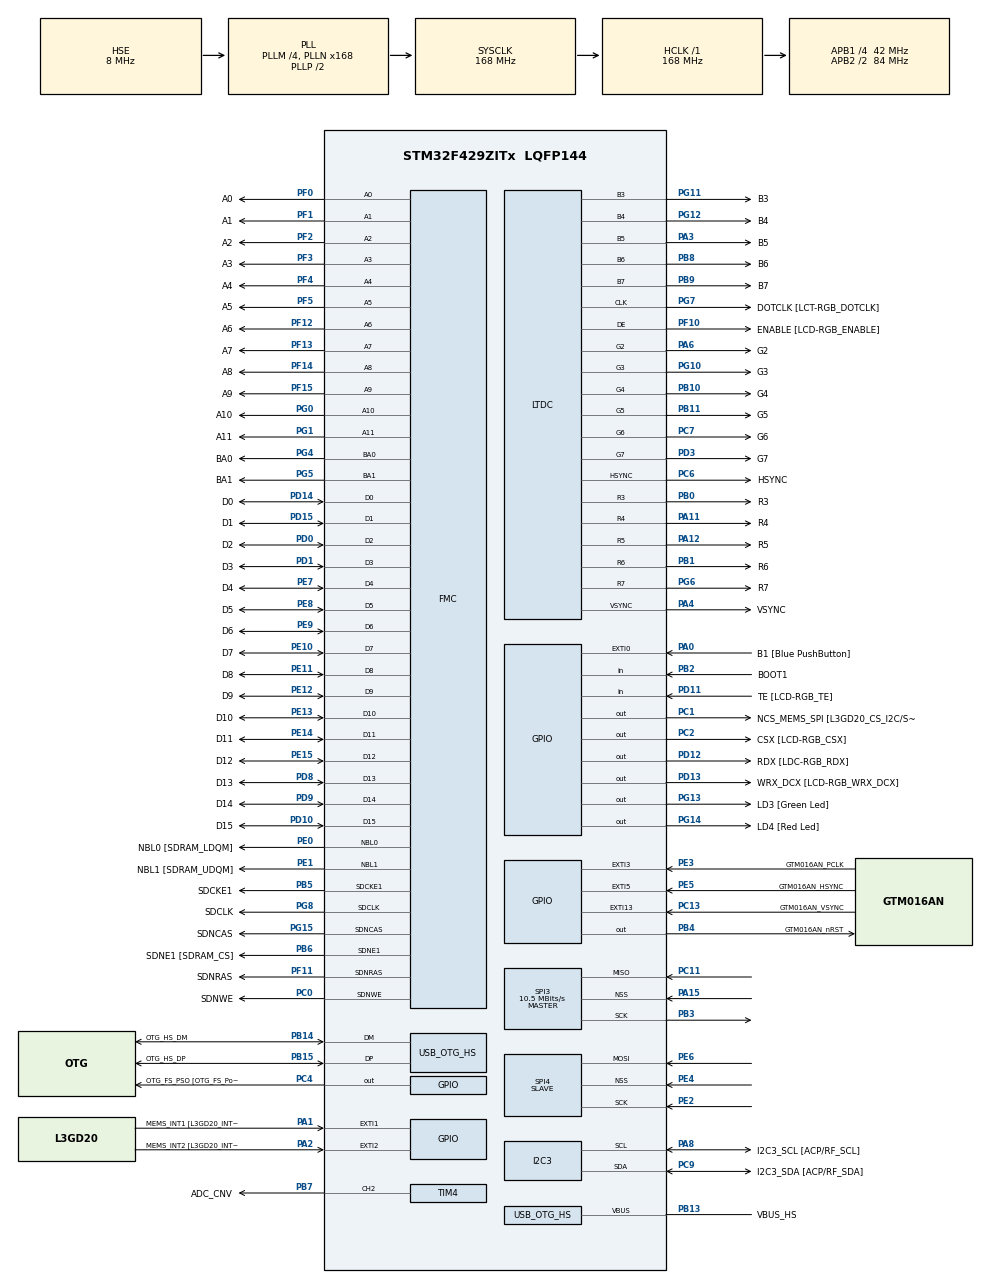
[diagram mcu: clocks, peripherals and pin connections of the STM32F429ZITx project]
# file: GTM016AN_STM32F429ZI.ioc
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Dma.I2C3_RX.1.Direction=DMA_PERIPH_TO_MEMORY
Dma.I2C3_RX.1.FIFOMode=DMA_FIFOMODE_DISABLE
Dma.I2C3_RX.1.Instance=DMA1_Stream2
Dma.I2C3_RX.1.MemDataAlignment=DMA_MDATAALIGN_BYTE
Dma.I2C3_RX.1.MemInc=DMA_MINC_ENABLE
Dma.I2C3_RX.1.Mode=DMA_NORMAL
Dma.I2C3_RX.1.PeriphDataAlignment=DMA_PDATAALIGN_BYTE
Dma.I2C3_RX.1.PeriphInc=DMA_PINC_DISABLE
Dma.I2C3_RX.1.Priority=DMA_PRIORITY_LOW
Dma.Request0=SPI4_RX
Dma.Request1=I2C3_RX
Dma.SPI4_RX.0.Direction=DMA_PERIPH_TO_MEMORY
Dma.SPI4_RX.0.FIFOMode=DMA_FIFOMODE_DISABLE
Dma.SPI4_RX.0.Instance=DMA2_Stream0
Dma.SPI4_RX.0.MemDataAlignment=DMA_MDATAALIGN_HALFWORD
Dma.SPI4_RX.0.MemInc=DMA_MINC_ENABLE
Dma.SPI4_RX.0.Mode=DMA_CIRCULAR
Dma.SPI4_RX.0.PeriphDataAlignment=DMA_PDATAALIGN_HALFWORD
Dma.SPI4_RX.0.PeriphInc=DMA_PINC_DISABLE
Dma.SPI4_RX.0.Priority=DMA_PRIORITY_LOW
FMC.CASLatency1=FMC_SDRAM_CAS_LATENCY_3
FMC.ExitSelfRefreshDelay1=7
FMC.LoadToActiveDelay1=2
FMC.RCDDelay1=2
FMC.RPDelay1=2
FMC.RPDelay2=2
FMC.ReadBurst1=FMC_SDRAM_RBURST_DISABLE
FMC.ReadPipeDelay1=FMC_SDRAM_RPIPE_DELAY_1
FMC.ReadPipeDelay2=FMC_SDRAM_RPIPE_DELAY_1
FMC.RowCycleDelay1=7
FMC.RowCycleDelay2=7
FMC.SDClockPeriod1=FMC_SDRAM_CLOCK_PERIOD_2
FMC.SDClockPeriod2=FMC_SDRAM_CLOCK_PERIOD_2
FMC.SelfRefreshTime1=4
FMC.WriteRecoveryTime1=3
LTDC.ActiveH=320
LTDC.ActiveW=240
LTDC.Alpha0_L0=0
LTDC.Alpha_L0=0
LTDC.BlendingFactor1_L0=LTDC_BLENDING_FACTOR1_CA
LTDC.BlendingFactor2_L0=LTDC_BLENDING_FACTOR2_CA
LTDC.FBStartAdress_L0=0
LTDC.HBP=20
LTDC.HFP=10
LTDC.HSync=10
LTDC.ImageHeight_L0=0
LTDC.ImageWidth_L0=0
LTDC.Layers=0
LTDC.PixelFormat_L0=LTDC_PIXEL_FORMAT_ARGB8888
LTDC.VFP=4
LTDC.VSync=2
LTDC.WindowX1_L0=240
LTDC.WindowY1_L0=320
Mcu.Family=STM32F4
Mcu.Name=STM32F429ZITx
Mcu.Package=LQFP144
NVIC.DMA1_Stream2_IRQn=true\:0\:0\:false\:false\:true\:false\:true
NVIC.DMA2D_IRQn=true\:5\:0\:true\:false\:true\:true\:true
NVIC.DMA2_Stream0_IRQn=true\:0\:0\:true\:false\:true\:true\:true
NVIC.EXTI0_IRQn=true\:1\:0\:true\:false\:true\:true\:true
NVIC.EXTI15_10_IRQn=true\:0\:0\:false\:false\:true\:true\:true
NVIC.EXTI3_IRQn=true\:0\:0\:true\:false\:true\:true\:true
NVIC.LTDC_IRQn=true\:5\:0\:true\:false\:true\:true\:true
NVIC.OTG_HS_IRQn=true\:1\:0\:true\:false\:true\:true\:true
NVIC.PriorityGroup=NVIC_PRIORITYGROUP_4
NVIC.TIM3_IRQn=true\:1\:0\:true\:false\:true\:true\:true
NVIC.TIM4_IRQn=true\:0\:0\:true\:false\:true\:true\:true
NVIC.TIM5_IRQn=true\:0\:0\:false\:false\:true\:true\:true
NVIC.TIM6_DAC_IRQn=true\:0\:0\:true\:false\:true\:false\:true
NVIC.TimeBase=TIM6_DAC_IRQn
NVIC.TimeBaseIP=TIM6
PA0/WKUP.GPIO_Label=B1 [Blue PushButton]
PA0/WKUP.GPIO_ModeDefaultEXTI=GPIO_MODE_IT_RISING
PA0/WKUP.GPIO_PuPd=GPIO_NOPULL
PA0/WKUP.Signal=GPXTI0
PA1.GPIO_Label=MEMS_INT1 [L3GD20_INT1]
PA1.GPIO_ModeDefaultEXTI=GPIO_MODE_EVT_RISING
PA1.GPIO_PuPd=GPIO_NOPULL
PA1.Signal=GPXTI1
PA10.GPIO_Label=STLINK_TX [STM32F103CBT6_PA2]
PA10.Signal=USART1_RX
PA11.GPIO_Label=R4
PA11.GPIO_Mode=GPIO_MODE_AF_PP
PA11.GPIO_PuPd=GPIO_NOPULL
PA11.GPIO_Speed=GPIO_SPEED_FREQ_LOW
PA11.Mode=RGB565
PA11.Signal=LTDC_R4
PA12.GPIO_Label=R5
PA12.GPIO_Mode=GPIO_MODE_AF_PP
PA12.GPIO_PuPd=GPIO_NOPULL
PA12.GPIO_Speed=GPIO_SPEED_FREQ_LOW
PA12.Mode=RGB565
PA12.Signal=LTDC_R5
PA13.GPIO_Label=SWDIO
PA13.Mode=Serial_Wire
PA13.Signal=SYS_JTMS-SWDIO
PA14.GPIO_Label=SWCLK
PA14.Mode=Serial_Wire
PA14.Signal=SYS_JTCK-SWCLK
PA15.Mode=NSS_Signal_Hard_Input
PA15.Signal=SPI3_NSS
PA2.GPIO_Label=MEMS_INT2 [L3GD20_INT2]
PA2.GPIO_ModeDefaultEXTI=GPIO_MODE_EVT_RISING
PA2.GPIO_PuPd=GPIO_NOPULL
PA2.Signal=GPXTI2
PA3.GPIO_Label=B5
PA3.GPIO_Mode=GPIO_MODE_AF_PP
PA3.GPIO_PuPd=GPIO_NOPULL
PA3.GPIO_Speed=GPIO_SPEED_FREQ_LOW
PA3.Mode=RGB565
PA3.Signal=LTDC_B5
PA4.GPIO_Label=VSYNC
PA4.GPIO_Mode=GPIO_MODE_AF_PP
PA4.GPIO_PuPd=GPIO_NOPULL
PA4.GPIO_Speed=GPIO_SPEED_FREQ_LOW
PA4.Mode=RGB565
PA4.Signal=LTDC_VSYNC
PA6.GPIO_Label=G2
PA6.GPIO_Mode=GPIO_MODE_AF_PP
PA6.GPIO_PuPd=GPIO_NOPULL
PA6.GPIO_Speed=GPIO_SPEED_FREQ_LOW
PA6.Mode=RGB565
PA6.Signal=LTDC_G2
PA8.GPIO_Label=I2C3_SCL [ACP/RF_SCL]
PA8.GPIO_Mode=GPIO_MODE_AF_OD
PA8.GPIO_PuPd=GPIO_NOPULL
PA8.GPIO_Speed=GPIO_SPEED_FREQ_LOW
PA8.Mode=I2C
PA8.Signal=I2C3_SCL
PA9.GPIO_Label=STLINK_RX [STM32F103CBT6_PA3]
PA9.Signal=USART1_TX
PB0.GPIO_Label=R3
PB0.GPIO_Mode=GPIO_MODE_AF_PP
PB0.GPIO_PuPd=GPIO_NOPULL
PB0.GPIO_Speed=GPIO_SPEED_FREQ_LOW
PB0.Mode=RGB565
PB0.Signal=LTDC_R3
PB1.GPIO_Label=R6
PB1.GPIO_Mode=GPIO_MODE_AF_PP
PB1.GPIO_PuPd=GPIO_NOPULL
PB1.GPIO_Speed=GPIO_SPEED_FREQ_LOW
PB1.Mode=RGB565
PB1.Signal=LTDC_R6
PB10.GPIO_Label=G4
PB10.GPIO_Mode=GPIO_MODE_AF_PP
PB10.GPIO_PuPd=GPIO_NOPULL
PB10.GPIO_Speed=GPIO_SPEED_FREQ_LOW
PB10.Mode=RGB565
PB10.Signal=LTDC_G4
PB11.GPIO_Label=G5
PB11.GPIO_Mode=GPIO_MODE_AF_PP
PB11.GPIO_PuPd=GPIO_NOPULL
PB11.GPIO_Speed=GPIO_SPEED_FREQ_LOW
PB11.Mode=RGB565
PB11.Signal=LTDC_G5
PB12.GPIO_Label=OTG_HS_ID
PB12.GPIO_Mode=GPIO_MODE_AF_PP
PB12.GPIO_PuPd=GPIO_NOPULL
PB12.GPIO_Speed=GPIO_SPEED_FREQ_LOW
PB12.Signal=USB_OTG_HS_ID
PB13.GPIO_Label=VBUS_HS
PB13.GPIO_Mode=GPIO_MODE_INPUT
PB13.GPIO_PuPd=GPIO_NOPULL
PB13.Mode=Activate_VBUS_FS
PB13.Signal=USB_OTG_HS_VBUS
PB14.GPIO_Label=OTG_HS_DM
PB14.GPIO_Mode=GPIO_MODE_AF_PP
PB14.GPIO_PuPd=GPIO_NOPULL
PB14.GPIO_Speed=GPIO_SPEED_FREQ_LOW
PB14.Mode=Device_Only_FS
PB14.Signal=USB_OTG_HS_DM
PB15.GPIO_Label=OTG_HS_DP
PB15.GPIO_Mode=GPIO_MODE_AF_PP
PB15.GPIO_PuPd=GPIO_NOPULL
PB15.GPIO_Speed=GPIO_SPEED_FREQ_LOW
PB15.Mode=Device_Only_FS
PB15.Signal=USB_OTG_HS_DP
PB2/BOOT1.GPIO_Label=BOOT1
PB2/BOOT1.GPIO_Mode=GPIO_MODE_INPUT
PB2/BOOT1.GPIO_PuPd=GPIO_NOPULL
PB2/BOOT1.Signal=GPIO_Input
PB3.Mode=RX_Only_Simplex_Unidirect_Master
PB3.Signal=SPI3_SCK
PB4.GPIO_Label=GTM016AN_nRST
PB4.Signal=GPIO_Output
PB5.GPIO_Label=SDCKE1
PB5.GPIO_Mode=GPIO_MODE_AF_PP
PB5.GPIO_PuPd=GPIO_NOPULL
PB5.GPIO_Speed=GPIO_SPEED_FREQ_VERY_HIGH
PB5.Mode=SdramChipSelect2_1
PB5.Signal=FMC_SDCKE1
PB6.GPIO_Label=SDNE1 [SDRAM_CS]
PB6.GPIO_Mode=GPIO_MODE_AF_PP
PB6.GPIO_PuPd=GPIO_NOPULL
PB6.GPIO_Speed=GPIO_SPEED_FREQ_VERY_HIGH
PB6.Mode=SdramChipSelect2_1
PB6.Signal=FMC_SDNE1
PB7.GPIO_Label=ADC_CNV
PB7.Signal=S_TIM4_CH2
PB8.GPIO_Label=B6
PB8.GPIO_Mode=GPIO_MODE_AF_PP
PB8.GPIO_PuPd=GPIO_NOPULL
PB8.GPIO_Speed=GPIO_SPEED_FREQ_LOW
PB8.Mode=RGB565
PB8.Signal=LTDC_B6
PB9.GPIO_Label=B7
PB9.GPIO_Mode=GPIO_MODE_AF_PP
PB9.GPIO_PuPd=GPIO_NOPULL
PB9.GPIO_Speed=GPIO_SPEED_FREQ_LOW
PB9.Mode=RGB565
PB9.Signal=LTDC_B7
PC0.GPIO_Label=SDNWE
PC0.GPIO_Mode=GPIO_MODE_AF_PP
PC0.GPIO_PuPd=GPIO_NOPULL
PC0.GPIO_Speed=GPIO_SPEED_FREQ_VERY_HIGH
PC0.Signal=FMC_SDNWE
PC1.GPIO_Label=NCS_MEMS_SPI [L3GD20_CS_I2C/SPI]
PC1.GPIO_Mode=GPIO_MODE_OUTPUT_PP
PC1.GPIO_PuPd=GPIO_NOPULL
PC1.GPIO_Speed=GPIO_SPEED_FREQ_LOW
PC1.Signal=GPIO_Output
PC10.GPIO_Label=R2
PC10.GPIO_Mode=GPIO_MODE_AF_PP
PC10.GPIO_PuPd=GPIO_NOPULL
PC10.GPIO_Speed=GPIO_SPEED_FREQ_LOW
PC10.Signal=LTDC_R2
PC11.Mode=RX_Only_Simplex_Unidirect_Master
PC11.Signal=SPI3_MISO
PC13.GPIO_Label=GTM016AN_VSYNC
PC13.Signal=GPXTI13
PC14/OSC32_IN.GPIO_Label=PC14-OSC32_IN
PC14/OSC32_IN.Signal=RCC_OSC32_IN
PC15/OSC32_OUT.GPIO_Label=PC15-OSC32_OUT
PC15/OSC32_OUT.Signal=RCC_OSC32_OUT
PC2.GPIO_Label=CSX [LCD-RGB_CSX]
PC2.GPIO_Mode=GPIO_MODE_OUTPUT_PP
PC2.GPIO_PuPd=GPIO_NOPULL
PC2.GPIO_Speed=GPIO_SPEED_FREQ_LOW
PC2.Signal=GPIO_Output
PC4.GPIO_Label=OTG_FS_PSO [OTG_FS_PowerSwitchOn]
PC4.GPIO_Mode=GPIO_MODE_OUTPUT_PP
PC4.GPIO_PuPd=GPIO_NOPULL
PC4.GPIO_Speed=GPIO_SPEED_FREQ_LOW
PC4.Signal=GPIO_Output
PC6.GPIO_Label=HSYNC
PC6.GPIO_Mode=GPIO_MODE_AF_PP
PC6.GPIO_PuPd=GPIO_NOPULL
PC6.GPIO_Speed=GPIO_SPEED_FREQ_LOW
PC6.Mode=RGB565
PC6.Signal=LTDC_HSYNC
PC7.GPIO_Label=G6
PC7.GPIO_Mode=GPIO_MODE_AF_PP
PC7.GPIO_PuPd=GPIO_NOPULL
PC7.GPIO_Speed=GPIO_SPEED_FREQ_LOW
PC7.Mode=RGB565
PC7.Signal=LTDC_G6
PC9.GPIO_Label=I2C3_SDA [ACP/RF_SDA]
PC9.GPIO_Mode=GPIO_MODE_AF_OD
PC9.GPIO_PuPd=GPIO_NOPULL
PC9.GPIO_Speed=GPIO_SPEED_FREQ_LOW
PC9.Mode=I2C
PC9.Signal=I2C3_SDA
PD0.GPIO_Label=D2
PD0.GPIO_Mode=GPIO_MODE_AF_PP
PD0.GPIO_PuPd=GPIO_NOPULL
PD0.GPIO_Speed=GPIO_SPEED_FREQ_VERY_HIGH
PD0.Signal=FMC_D2_DA2
PD1.GPIO_Label=D3
PD1.GPIO_Mode=GPIO_MODE_AF_PP
PD1.GPIO_PuPd=GPIO_NOPULL
PD1.GPIO_Speed=GPIO_SPEED_FREQ_VERY_HIGH
PD1.Signal=FMC_D3_DA3
PD10.GPIO_Label=D15
PD10.GPIO_Mode=GPIO_MODE_AF_PP
PD10.GPIO_PuPd=GPIO_NOPULL
PD10.GPIO_Speed=GPIO_SPEED_FREQ_VERY_HIGH
PD10.Signal=FMC_D15_DA15
PD11.GPIO_Label=TE [LCD-RGB_TE]
PD11.GPIO_Mode=GPIO_MODE_INPUT
PD11.GPIO_PuPd=GPIO_NOPULL
PD11.Signal=GPIO_Input
PD12.GPIO_Label=RDX [LDC-RGB_RDX]
PD12.GPIO_Mode=GPIO_MODE_OUTPUT_PP
PD12.GPIO_PuPd=GPIO_NOPULL
PD12.GPIO_Speed=GPIO_SPEED_FREQ_LOW
PD12.Signal=GPIO_Output
PD13.GPIO_Label=WRX_DCX [LCD-RGB_WRX_DCX]
PD13.GPIO_Mode=GPIO_MODE_OUTPUT_PP
PD13.GPIO_PuPd=GPIO_NOPULL
PD13.GPIO_Speed=GPIO_SPEED_FREQ_LOW
PD13.Signal=GPIO_Output
PD14.GPIO_Label=D0
PD14.GPIO_Mode=GPIO_MODE_AF_PP
PD14.GPIO_PuPd=GPIO_NOPULL
PD14.GPIO_Speed=GPIO_SPEED_FREQ_VERY_HIGH
PD14.Signal=FMC_D0_DA0
PD15.GPIO_Label=D1
PD15.GPIO_Mode=GPIO_MODE_AF_PP
PD15.GPIO_PuPd=GPIO_NOPULL
PD15.GPIO_Speed=GPIO_SPEED_FREQ_VERY_HIGH
PD15.Signal=FMC_D1_DA1
PD3.GPIO_Label=G7
PD3.GPIO_Mode=GPIO_MODE_AF_PP
PD3.GPIO_PuPd=GPIO_NOPULL
PD3.GPIO_Speed=GPIO_SPEED_FREQ_LOW
PD3.Mode=RGB565
PD3.Signal=LTDC_G7
PD6.GPIO_Label=B2
PD6.GPIO_Mode=GPIO_MODE_AF_PP
PD6.GPIO_PuPd=GPIO_NOPULL
PD6.GPIO_Speed=GPIO_SPEED_FREQ_LOW
PD6.Signal=LTDC_B2
PD8.GPIO_Label=D13
PD8.GPIO_Mode=GPIO_MODE_AF_PP
PD8.GPIO_PuPd=GPIO_NOPULL
PD8.GPIO_Speed=GPIO_SPEED_FREQ_VERY_HIGH
PD8.Signal=FMC_D13_DA13
PD9.GPIO_Label=D14
PD9.GPIO_Mode=GPIO_MODE_AF_PP
PD9.GPIO_PuPd=GPIO_NOPULL
PD9.GPIO_Speed=GPIO_SPEED_FREQ_VERY_HIGH
PD9.Signal=FMC_D14_DA14
PE0.GPIO_Label=NBL0 [SDRAM_LDQM]
PE0.GPIO_Mode=GPIO_MODE_AF_PP
PE0.GPIO_PuPd=GPIO_NOPULL
PE0.GPIO_Speed=GPIO_SPEED_FREQ_VERY_HIGH
PE0.Signal=FMC_NBL0
PE1.GPIO_Label=NBL1 [SDRAM_UDQM]
PE1.GPIO_Mode=GPIO_MODE_AF_PP
PE1.GPIO_PuPd=GPIO_NOPULL
PE1.GPIO_Speed=GPIO_SPEED_FREQ_VERY_HIGH
PE1.Signal=FMC_NBL1
PE10.GPIO_Label=D7
PE10.GPIO_Mode=GPIO_MODE_AF_PP
PE10.GPIO_PuPd=GPIO_NOPULL
PE10.GPIO_Speed=GPIO_SPEED_FREQ_VERY_HIGH
PE10.Signal=FMC_D7_DA7
PE11.GPIO_Label=D8
PE11.GPIO_Mode=GPIO_MODE_AF_PP
PE11.GPIO_PuPd=GPIO_NOPULL
PE11.GPIO_Speed=GPIO_SPEED_FREQ_VERY_HIGH
PE11.Signal=FMC_D8_DA8
PE12.GPIO_Label=D9
PE12.GPIO_Mode=GPIO_MODE_AF_PP
PE12.GPIO_PuPd=GPIO_NOPULL
PE12.GPIO_Speed=GPIO_SPEED_FREQ_VERY_HIGH
PE12.Signal=FMC_D9_DA9
PE13.GPIO_Label=D10
PE13.GPIO_Mode=GPIO_MODE_AF_PP
PE13.GPIO_PuPd=GPIO_NOPULL
PE13.GPIO_Speed=GPIO_SPEED_FREQ_VERY_HIGH
PE13.Signal=FMC_D10_DA10
PE14.GPIO_Label=D11
PE14.GPIO_Mode=GPIO_MODE_AF_PP
PE14.GPIO_PuPd=GPIO_NOPULL
PE14.GPIO_Speed=GPIO_SPEED_FREQ_VERY_HIGH
PE14.Signal=FMC_D11_DA11
PE15.GPIO_Label=D12
PE15.GPIO_Mode=GPIO_MODE_AF_PP
PE15.GPIO_PuPd=GPIO_NOPULL
PE15.GPIO_Speed=GPIO_SPEED_FREQ_VERY_HIGH
PE15.Signal=FMC_D12_DA12
PE2.Mode=RX_Only_Simplex_Unidirect_Slave
PE2.Signal=SPI4_SCK
PE3.GPIO_Label=GTM016AN_PCLK
PE3.Signal=GPXTI3
PE4.Mode=NSS_Signal_Hard_Input
PE4.Signal=SPI4_NSS
PE5.GPIO_Label=GTM016AN_HSYNC
PE5.Signal=GPXTI5
PE6.Mode=RX_Only_Simplex_Unidirect_Slave
PE6.Signal=SPI4_MOSI
PE7.GPIO_Label=D4
PE7.GPIO_Mode=GPIO_MODE_AF_PP
PE7.GPIO_PuPd=GPIO_NOPULL
PE7.GPIO_Speed=GPIO_SPEED_FREQ_VERY_HIGH
PE7.Signal=FMC_D4_DA4
PE8.GPIO_Label=D5
PE8.GPIO_Mode=GPIO_MODE_AF_PP
PE8.GPIO_PuPd=GPIO_NOPULL
PE8.GPIO_Speed=GPIO_SPEED_FREQ_VERY_HIGH
PE8.Signal=FMC_D5_DA5
PE9.GPIO_Label=D6
PE9.GPIO_Mode=GPIO_MODE_AF_PP
PE9.GPIO_PuPd=GPIO_NOPULL
PE9.GPIO_Speed=GPIO_SPEED_FREQ_VERY_HIGH
PE9.Signal=FMC_D6_DA6
PF0.GPIO_Label=A0
PF0.GPIO_Mode=GPIO_MODE_AF_PP
PF0.GPIO_PuPd=GPIO_NOPULL
PF0.GPIO_Speed=GPIO_SPEED_FREQ_VERY_HIGH
PF0.Signal=FMC_A0
PF1.GPIO_Label=A1
PF1.GPIO_Mode=GPIO_MODE_AF_PP
PF1.GPIO_PuPd=GPIO_NOPULL
PF1.GPIO_Speed=GPIO_SPEED_FREQ_VERY_HIGH
PF1.Signal=FMC_A1
PF10.GPIO_Label=ENABLE [LCD-RGB_ENABLE]
PF10.GPIO_Mode=GPIO_MODE_AF_PP
PF10.GPIO_PuPd=GPIO_NOPULL
PF10.GPIO_Speed=GPIO_SPEED_FREQ_LOW
PF10.Mode=RGB565
PF10.Signal=LTDC_DE
PF11.GPIO_Label=SDNRAS
PF11.GPIO_Mode=GPIO_MODE_AF_PP
PF11.GPIO_PuPd=GPIO_NOPULL
PF11.GPIO_Speed=GPIO_SPEED_FREQ_VERY_HIGH
PF11.Signal=FMC_SDNRAS
PF12.GPIO_Label=A6
PF12.GPIO_Mode=GPIO_MODE_AF_PP
PF12.GPIO_PuPd=GPIO_NOPULL
PF12.GPIO_Speed=GPIO_SPEED_FREQ_VERY_HIGH
PF12.Signal=FMC_A6
PF13.GPIO_Label=A7
PF13.GPIO_Mode=GPIO_MODE_AF_PP
PF13.GPIO_PuPd=GPIO_NOPULL
PF13.GPIO_Speed=GPIO_SPEED_FREQ_VERY_HIGH
PF13.Signal=FMC_A7
PF14.GPIO_Label=A8
PF14.GPIO_Mode=GPIO_MODE_AF_PP
PF14.GPIO_PuPd=GPIO_NOPULL
PF14.GPIO_Speed=GPIO_SPEED_FREQ_VERY_HIGH
PF14.Signal=FMC_A8
PF15.GPIO_Label=A9
PF15.GPIO_Mode=GPIO_MODE_AF_PP
PF15.GPIO_PuPd=GPIO_NOPULL
PF15.GPIO_Speed=GPIO_SPEED_FREQ_VERY_HIGH
PF15.Signal=FMC_A9
PF2.GPIO_Label=A2
PF2.GPIO_Mode=GPIO_MODE_AF_PP
PF2.GPIO_PuPd=GPIO_NOPULL
PF2.GPIO_Speed=GPIO_SPEED_FREQ_VERY_HIGH
PF2.Signal=FMC_A2
PF3.GPIO_Label=A3
PF3.GPIO_Mode=GPIO_MODE_AF_PP
PF3.GPIO_PuPd=GPIO_NOPULL
PF3.GPIO_Speed=GPIO_SPEED_FREQ_VERY_HIGH
PF3.Signal=FMC_A3
PF4.GPIO_Label=A4
PF4.GPIO_Mode=GPIO_MODE_AF_PP
PF4.GPIO_PuPd=GPIO_NOPULL
PF4.GPIO_Speed=GPIO_SPEED_FREQ_VERY_HIGH
PF4.Signal=FMC_A4
PF5.GPIO_Label=A5
PF5.GPIO_Mode=GPIO_MODE_AF_PP
PF5.GPIO_PuPd=GPIO_NOPULL
PF5.GPIO_Speed=GPIO_SPEED_FREQ_VERY_HIGH
PF5.Signal=FMC_A5
PF7.GPIO_Label=SPI5_SCK [L3GD20_SCL/SPC]
PF7.GPIO_Mode=GPIO_MODE_AF_PP
PF7.GPIO_PuPd=GPIO_NOPULL
PF7.GPIO_Speed=GPIO_SPEED_FREQ_LOW
PF7.Signal=SPI5_SCK
PF8.GPIO_Label=SPI5_MISO [L3GD20_SDO]
PF8.GPIO_Mode=GPIO_MODE_AF_PP
PF8.GPIO_PuPd=GPIO_NOPULL
PF8.GPIO_Speed=GPIO_SPEED_FREQ_LOW
PF8.Signal=SPI5_MISO
PF9.GPIO_Label=SPI5_MOSI [L3GD20_SDA/SDI/SDO]
PF9.GPIO_Mode=GPIO_MODE_AF_PP
PF9.GPIO_PuPd=GPIO_NOPULL
PF9.GPIO_Speed=GPIO_SPEED_FREQ_LOW
PF9.Signal=SPI5_MOSI
PG0.GPIO_Label=A10
PG0.GPIO_Mode=GPIO_MODE_AF_PP
PG0.GPIO_PuPd=GPIO_NOPULL
PG0.GPIO_Speed=GPIO_SPEED_FREQ_VERY_HIGH
PG0.Signal=FMC_A10
PG1.GPIO_Label=A11
PG1.GPIO_Mode=GPIO_MODE_AF_PP
PG1.GPIO_PuPd=GPIO_NOPULL
PG1.GPIO_Speed=GPIO_SPEED_FREQ_VERY_HIGH
PG1.Signal=FMC_A11
PG10.GPIO_Label=G3
PG10.GPIO_Mode=GPIO_MODE_AF_PP
PG10.GPIO_PuPd=GPIO_NOPULL
PG10.GPIO_Speed=GPIO_SPEED_FREQ_LOW
PG10.Mode=RGB565
PG10.Signal=LTDC_G3
PG11.GPIO_Label=B3
PG11.GPIO_Mode=GPIO_MODE_AF_PP
PG11.GPIO_PuPd=GPIO_NOPULL
PG11.GPIO_Speed=GPIO_SPEED_FREQ_LOW
PG11.Mode=RGB565
PG11.Signal=LTDC_B3
PG12.GPIO_Label=B4
PG12.GPIO_Mode=GPIO_MODE_AF_PP
PG12.GPIO_PuPd=GPIO_NOPULL
PG12.GPIO_Speed=GPIO_SPEED_FREQ_LOW
PG12.Mode=RGB565
PG12.Signal=LTDC_B4
PG13.GPIO_Label=LD3 [Green Led]
PG13.GPIO_Mode=GPIO_MODE_OUTPUT_PP
PG13.GPIO_PuPd=GPIO_NOPULL
PG13.GPIO_Speed=GPIO_SPEED_FREQ_LOW
PG13.Signal=GPIO_Output
PG14.GPIO_Label=LD4 [Red Led]
PG14.GPIO_Mode=GPIO_MODE_OUTPUT_PP
PG14.GPIO_PuPd=GPIO_NOPULL
PG14.GPIO_Speed=GPIO_SPEED_FREQ_LOW
PG14.Signal=GPIO_Output
PG15.GPIO_Label=SDNCAS
PG15.GPIO_Mode=GPIO_MODE_AF_PP
PG15.GPIO_PuPd=GPIO_NOPULL
PG15.GPIO_Speed=GPIO_SPEED_FREQ_VERY_HIGH
PG15.Signal=FMC_SDNCAS
PG4.GPIO_Label=BA0
PG4.GPIO_Mode=GPIO_MODE_AF_PP
PG4.GPIO_PuPd=GPIO_NOPULL
PG4.GPIO_Speed=GPIO_SPEED_FREQ_VERY_HIGH
PG4.Signal=FMC_A14_BA0
PG5.GPIO_Label=BA1
PG5.GPIO_Mode=GPIO_MODE_AF_PP
PG5.GPIO_PuPd=GPIO_NOPULL
PG5.GPIO_Speed=GPIO_SPEED_FREQ_VERY_HIGH
PG5.Signal=FMC_A15_BA1
PG6.GPIO_Label=R7
PG6.GPIO_Mode=GPIO_MODE_AF_PP
PG6.GPIO_PuPd=GPIO_NOPULL
PG6.GPIO_Speed=GPIO_SPEED_FREQ_LOW
PG6.Mode=RGB565
PG6.Signal=LTDC_R7
PG7.GPIO_Label=DOTCLK [LCT-RGB_DOTCLK]
PG7.GPIO_Mode=GPIO_MODE_AF_PP
PG7.GPIO_PuPd=GPIO_NOPULL
PG7.GPIO_Speed=GPIO_SPEED_FREQ_LOW
PG7.Mode=RGB565
PG7.Signal=LTDC_CLK
PG8.GPIO_Label=SDCLK
PG8.GPIO_Mode=GPIO_MODE_AF_PP
PG8.GPIO_PuPd=GPIO_NOPULL
PG8.GPIO_Speed=GPIO_SPEED_FREQ_VERY_HIGH
PG8.Signal=FMC_SDCLK
PH0/OSC_IN.GPIO_Label=PH0-OSC_IN
PH0/OSC_IN.Mode=HSE-External-Oscillator
PH0/OSC_IN.Signal=RCC_OSC_IN
PH1/OSC_OUT.GPIO_Label=PH1-OSC_OUT
PH1/OSC_OUT.Mode=HSE-External-Oscillator
PH1/OSC_OUT.Signal=RCC_OSC_OUT
ProjectManager.HeapSize=0x2000
ProjectManager.StackSize=0x4000
ProjectManager.TargetToolchain=MDK-ARM V5.27
RCC.48MHZClocksFreq_Value=48000000
RCC.AHBFreq_Value=168000000
RCC.APB1CLKDivider=RCC_HCLK_DIV4
RCC.APB1Freq_Value=42000000
RCC.APB1TimFreq_Value=84000000
RCC.APB2CLKDivider=RCC_HCLK_DIV2
RCC.APB2Freq_Value=84000000
RCC.APB2TimFreq_Value=168000000
RCC.CortexFreq_Value=168000000
RCC.HCLKFreq_Value=168000000
RCC.HSE_VALUE=8000000
RCC.HSI_VALUE=16000000
RCC.LSE_VALUE=32768
RCC.PLLM=4
RCC.PLLN=168
RCC.PLLQ=7
RCC.PLLSAIN=50
RCC.SYSCLKFreq_VALUE=168000000
RCC.SYSCLKSource=RCC_SYSCLKSOURCE_PLLCLK
RCC.VCOOutputFreq_Value=336000000
SH.FMC_A0.0=FMC_A0,12b-sda1
SH.FMC_A1.0=FMC_A1,12b-sda1
SH.FMC_A10.0=FMC_A10,12b-sda1
SH.FMC_A11.0=FMC_A11,12b-sda1
SH.FMC_A14_BA0.0=FMC_BA0,FourSdramBanks1
SH.FMC_A15_BA1.0=FMC_BA1,FourSdramBanks1
SH.FMC_A2.0=FMC_A2,12b-sda1
SH.FMC_A3.0=FMC_A3,12b-sda1
SH.FMC_A4.0=FMC_A4,12b-sda1
SH.FMC_A5.0=FMC_A5,12b-sda1
SH.FMC_A6.0=FMC_A6,12b-sda1
SH.FMC_A7.0=FMC_A7,12b-sda1
SH.FMC_A8.0=FMC_A8,12b-sda1
SH.FMC_A9.0=FMC_A9,12b-sda1
SH.FMC_D0_DA0.0=FMC_D0,sd-16b-d1
SH.FMC_D10_DA10.0=FMC_D10,sd-16b-d1
SH.FMC_D11_DA11.0=FMC_D11,sd-16b-d1
SH.FMC_D12_DA12.0=FMC_D12,sd-16b-d1
SH.FMC_D13_DA13.0=FMC_D13,sd-16b-d1
SH.FMC_D14_DA14.0=FMC_D14,sd-16b-d1
SH.FMC_D15_DA15.0=FMC_D15,sd-16b-d1
SH.FMC_D1_DA1.0=FMC_D1,sd-16b-d1
SH.FMC_D2_DA2.0=FMC_D2,sd-16b-d1
SH.FMC_D3_DA3.0=FMC_D3,sd-16b-d1
SH.FMC_D4_DA4.0=FMC_D4,sd-16b-d1
SH.FMC_D5_DA5.0=FMC_D5,sd-16b-d1
SH.FMC_D6_DA6.0=FMC_D6,sd-16b-d1
SH.FMC_D7_DA7.0=FMC_D7,sd-16b-d1
SH.FMC_D8_DA8.0=FMC_D8,sd-16b-d1
SH.FMC_D9_DA9.0=FMC_D9,sd-16b-d1
SH.FMC_NBL0.0=FMC_NBL0,Sd2ByteEnable1
SH.FMC_NBL1.0=FMC_NBL1,Sd2ByteEnable1
SH.FMC_SDCLK.0=FMC_SDCLK,12b-sda1
SH.FMC_SDNCAS.0=FMC_SDNCAS,12b-sda1
SH.FMC_SDNRAS.0=FMC_SDNRAS,12b-sda1
SH.FMC_SDNWE.0=FMC_SDNWE,12b-sda1
SH.S_TIM4_CH2.0=TIM4_CH2,PWM Generation2 CH2
SPI3.BaudRatePrescaler=SPI_BAUDRATEPRESCALER_4
SPI3.CLKPolarity=SPI_POLARITY_LOW
SPI3.CalculateBaudRate=10.5 MBits/s
SPI3.DataSize=SPI_DATASIZE_16BIT
SPI3.Direction=SPI_DIRECTION_2LINES_RXONLY
SPI3.Mode=SPI_MODE_MASTER
SPI3.VirtualNSS=VM_NSSHARD
SPI3.VirtualType=VM_MASTER
SPI4.DataSize=SPI_DATASIZE_16BIT
SPI4.Direction=SPI_DIRECTION_2LINES_RXONLY
SPI4.Mode=SPI_MODE_SLAVE
SPI4.VirtualNSS=VM_NSSHARD
SPI4.VirtualType=VM_SLAVE
TIM3.AutoReloadPreload=TIM_AUTORELOAD_PRELOAD_ENABLE
TIM3.Period=139
TIM3.Prescaler=59999
TIM3.TIM_MasterSlaveMode=TIM_MASTERSLAVEMODE_DISABLE
TIM4.AutoReloadPreload=TIM_AUTORELOAD_PRELOAD_ENABLE
TIM4.Channel-PWM\ Generation2\ CH2=TIM_CHANNEL_2
TIM4.OCMode_PWM-PWM\ Generation2\ CH2=TIM_OCMODE_PWM1
TIM4.OCPolarity_2=TIM_OCPOLARITY_LOW
TIM4.Period=639
TIM4.Prescaler=0
TIM4.Pulse-PWM\ Generation2\ CH2=1
TIM4.TIM_MasterOutputTrigger=TIM_TRGO_RESET
TIM4.TIM_MasterSlaveMode=TIM_MASTERSLAVEMODE_DISABLE
TIM5.Channel-PWM\ Generation1\ No\ Output=TIM_CHANNEL_1
TIM5.Period=600
TIM5.Prescaler=0
TIM5.Pulse-PWM\ Generation1\ No\ Output=600
USB_DEVICE.CLASS_NAME_HS=CDC
USB_DEVICE.VirtualMode-CDC_HS=Cdc
USB_DEVICE.VirtualModeHS=Cdc_HS
USB_OTG_HS.VirtualMode-Device_Only_FS=Device_Only_FS
VP_DMA2D_VS_DMA2D.Mode=DMA2D_Activate
VP_SYS_VS_tim6.Mode=TIM6
VP_TIM3_VS_ClockSourceINT.Mode=Internal
VP_TIM4_VS_ClockSourceINT.Mode=Internal
VP_TIM4_VS_OPM.Mode=OPM_bit
VP_TIM5_VS_ClockSourceINT.Mode=Internal
VP_TIM5_VS_OPM.Mode=OPM_bit
VP_TIM5_VS_no_output1.Mode=PWM Generation1 No Output
VP_USB_DEVICE_VS_USB_DEVICE_CDC_HS.Mode=CDC_HS
board=STM32F429I-DISC1

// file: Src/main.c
/* USER CODE BEGIN Header */
/**
  ******************************************************************************
  * @file           : main.c
  * @brief          : Main program body
  ******************************************************************************
  * @attention
  *
  * <h2><center>&copy; Copyright (c) 2020 STMicroelectronics.
  * All rights reserved.</center></h2>
  *
  * This software component is licensed by ST under Ultimate Liberty license
  * SLA0044, the "License"; You may not use this file except in compliance with
  * the License. You may obtain a copy of the License at:
  *                             www.st.com/SLA0044
  *
  ******************************************************************************
  */
/* USER CODE END Header */
#include "main.h"
#include "dma.h"
#include "dma2d.h"
#include "i2c.h"
#include "ltdc.h"
#include "spi.h"
#include "tim.h"
#include "usb_device.h"
#include "gpio.h"
#include "fmc.h"

/* USER CODE BEGIN Includes */

#include "stm32f4xx_hal_def.h"
#include "usbd_cdc_if.h"
#include "UI.h"

/* USER CODE END Includes */

/* USER CODE BEGIN PV */

uint8_t shift_=10,direct_=0;

ADC_SRC ADC_select=ADC_External;//Test;
extern frame_BufferTypeDef img;
extern ui_TypeDef ui;

USER_CDC_PACKAGE_TYPE_t user_cdc_buffer;	// cdc package buffer
uint8_t commands[4];	// cdc command buffer

// i2c control value buffer
uint8_t ctrlBuffer[100];	// i2c read/write all (addr 0 to 99)
uint16_t imageValue[22];

// current frame size
uint8_t frameSizeWidth=22;
uint8_t frameSizeHeight=22;

// 2 times image buffer from spi
uint8_t imagBuffer[2*22*22*2+2];	// double buffer * 22x22 pixels * 2bytes/pxl

// image pointer
uint8_t imgRead=0;
// double frame buffer selector
uint8_t frameReady=1;
uint8_t ready=0;
// uint8_t sync=0;

/* USER CODE END PV */

void SystemClock_Config(void);

/* USER CODE BEGIN 0 */

//void HAL_SPI_RxCpltCallback(SPI_HandleTypeDef *hspi){
//	for(uint16_t i=0;i<484;i+=23){
//		imageValue[i/23]=img.image[0][i];
//	}
//}

// first read frame size on system startup
//void getFrameSize(){
//  commands[0]=28;
//  HAL_I2C_Master_Transmit(&hi2c3,0x40,commands,1,10);
//  HAL_I2C_Master_Receive(&hi2c3,0x40,&ctrlBuffer[28],1,10);
//  commands[0]=30;
//  HAL_I2C_Master_Transmit(&hi2c3,0x40,commands,1,10);
//  HAL_I2C_Master_Receive(&hi2c3,0x40,&ctrlBuffer[30],1,10);
//  commands[0]=32;
//  HAL_I2C_Master_Transmit(&hi2c3,0x40,commands,1,10);
//  HAL_I2C_Master_Receive(&hi2c3,0x40,&ctrlBuffer[32],1,10);
//  commands[0]=34;
//  HAL_I2C_Master_Transmit(&hi2c3,0x40,commands,1,10);
//  HAL_I2C_Master_Receive(&hi2c3,0x40,&ctrlBuffer[34],1,10);

//  ctrlBuffer[32]=21;
//  ctrlBuffer[34]=21;
//  ctrlBuffer[28]=0;
//  ctrlBuffer[30]=0;

//  if(0<ctrlBuffer[32]-ctrlBuffer[28]+1 && ctrlBuffer[32]-ctrlBuffer[28]+1<23){
//    frameSizeWidth=ctrlBuffer[32]-ctrlBuffer[28]+1;
//  }
//  if(0<ctrlBuffer[34]-ctrlBuffer[30]+1 && ctrlBuffer[34]-ctrlBuffer[30]+1<23){
//    frameSizeHeight=ctrlBuffer[34]-ctrlBuffer[30]+1;
//  }
//}

//--------------
void HAL_GPIO_EXTI_Callback(uint16_t GPIO_Pin){
	if(GPIO_Pin==GTM016AN_PCLK_Pin){
		HAL_GPIO_TogglePin(LD4_GPIO_Port,LD4_Pin);
			__HAL_TIM_ENABLE_IT(&htim4, TIM_IT_CC2);
			__HAL_TIM_ENABLE(&htim4);
			__HAL_TIM_ENABLE_IT(&htim5, TIM_IT_CC1);
			__HAL_TIM_ENABLE(&htim5);
//			HAL_TIM_PWM_Start_IT(&htim4,TIM_CHANNEL_2);
//			HAL_TIM_PWM_Start_IT(&htim5,TIM_CHANNEL_1);
	}
  if(GPIO_Pin==GTM016AN_VSYNC_Pin){
			HAL_GPIO_TogglePin(LD3_GPIO_Port,LD3_Pin);
		if(ADC_select==ADC_Internal){
//			HAL_SPI_Receive_DMA(&hspi4,(uint8_t*)img.image,968);
//			HAL_NVIC_DisableIRQ(GTM016AN_VSYNC_EXTI_IRQn);
//			HAL_NVIC_DisableIRQ(GTM016AN_PCLK_EXTI_IRQn);
		}
//		else if(ADC_select==ADC_External){
//			// preset external adc pointer
//			img.pixel=483;	// PCLK rising after Vsync fell is pixel (21,21)
//		}
  }
  if(GPIO_Pin==B1_Pin){
		HAL_NVIC_DisableIRQ(B1_Pin);
		// change source
		ADC_select=(ADC_select<1)? (ADC_select+1):ADC_Test;
		// update ADC source
		setADC(ADC_select);
		HAL_NVIC_EnableIRQ(B1_Pin);
  }
}

//void HAL_SPI_RxHalfCpltCallback(SPI_HandleTypeDef *hspi){
//	img.frame=0;
//	if( img.pixel==  0 || img.pixel== 23 ||
//				img.pixel== 46 || img.pixel== 69 ||
//				img.pixel== 92 || img.pixel==115 ||
//				img.pixel==138 || img.pixel==161 ||
//				img.pixel==184 || img.pixel==207 ||
//				img.pixel==230 || img.pixel==253 ||
//				img.pixel==276 || img.pixel==299 ||
//				img.pixel==322 || img.pixel==345 ||
//				img.pixel==368 || img.pixel==391 ||
//				img.pixel==414 || img.pixel==437 ||
//				img.pixel==460 || img.pixel==483){
//			imageValue[img.pixel/23]=img.image[0][img.pixel];
//			img.image[img.frame][img.pixel]=0;
//		}
//		img.pixel=(img.pixel<483)? img.pixel+1:0;
//}

//void HAL_SPI_RxCpltCallback(SPI_HandleTypeDef *hspi){
//	img.frame=1;
//	if( img.pixel==  0 || img.pixel== 23 ||
//				img.pixel== 46 || img.pixel== 69 ||
//				img.pixel== 92 || img.pixel==115 ||
//				img.pixel==138 || img.pixel==161 ||
//				img.pixel==184 || img.pixel==207 ||
//				img.pixel==230 || img.pixel==253 ||
//				img.pixel==276 || img.pixel==299 ||
//				img.pixel==322 || img.pixel==345 ||
//				img.pixel==368 || img.pixel==391 ||
//				img.pixel==414 || img.pixel==437 ||
//				img.pixel==460 || img.pixel==483){
//			imageValue[img.pixel/23]=img.image[0][img.pixel];
//			img.image[img.frame][img.pixel]=0;
//		}
//		img.pixel=(img.pixel<483)? img.pixel+1:0;
//}

/* USER CODE END 0 */

int main(void)
{

  /* MCU Configuration--------------------------------------------------------*/

  /* Reset of all peripherals, Initializes the Flash interface and the Systick. */
  HAL_Init();

  /* Configure the system clock */
  SystemClock_Config();

  /* Initialize all configured peripherals */
  MX_GPIO_Init();
  MX_DMA_Init();
  MX_DMA2D_Init();
  MX_FMC_Init();
  MX_LTDC_Init();
  MX_SPI3_Init();
  MX_SPI4_Init();
  MX_USB_DEVICE_Init();
  MX_TIM3_Init();
  MX_TIM4_Init();
  MX_TIM5_Init();
  MX_I2C3_Init();
  /* USER CODE BEGIN 2 */

	// stop external adc cnv clock and pclk
	HAL_NVIC_DisableIRQ(GTM016AN_VSYNC_EXTI_IRQn);
	HAL_NVIC_DisableIRQ(GTM016AN_PCLK_EXTI_IRQn);
	HAL_GPIO_WritePin(GTM016AN_nRST_GPIO_Port,GTM016AN_nRST_Pin,GPIO_PIN_SET);
	UI_Initial(LOGO_COLOUR,FONT_COLOUR,BACK_COLOUR);

//	HAL_SPI_Receive(&hspi4,(uint8_t*)img.image+img.pixel*2,1,1);
//	HAL_TIM_PWM_Start_IT(&htim4,TIM_CHANNEL_2);
//	setADC(ADC_select);

	// software PCLK clock generator
	HAL_TIM_Base_Start_IT(&htim3);

  /* USER CODE END 2 */

  /* Infinite loop */
  /* USER CODE BEGIN WHILE */
  while (1)
  {

    // cdc command handler
//		if(user_cdc_buffer.len>0){
//      switch(user_cdc_buffer.data[0]){
//      // read frame size
//        case 10:
//          if(ctrlBuffer[32]-ctrlBuffer[28]+1>0){
//            frameSizeWidth=ctrlBuffer[32]-ctrlBuffer[28]+1;
//          }
//          commands[0]=10; //ack
//          commands[1]=frameSizeWidth;
//          commands[2]=ctrlBuffer[28];
//          commands[3]=ctrlBuffer[32];
//          CDC_Transmit_HS(commands,4);
//          break;
//        case 11:
//          if(ctrlBuffer[34]-ctrlBuffer[30]+1>0){
//            frameSizeHeight=ctrlBuffer[34]-ctrlBuffer[30]+1;
//          }
//          commands[0]=11; //ack
//          commands[1]=frameSizeHeight;
//          commands[2]=ctrlBuffer[30];
//          commands[3]=ctrlBuffer[34];
//          CDC_Transmit_HS(commands,4);
//          break;
//      // read imgBuffer
//        case 17:
//          imgRead=1;
//          break;
//      // read calibration
//        case 20:
//          imgRead=2;
//          break;
//      /**
//       * i2c write special address
//       *   cdc => ctrlBuffer[x]
//       *   ack + ctrlBuffer[x] => cdc ack(1 bytes)
//       */
//        case 33:
//          ctrlBuffer[user_cdc_buffer.data[1]]=user_cdc_buffer.data[2];
//          commands[0]=user_cdc_buffer.data[1];
//          commands[1]=user_cdc_buffer.data[2];
//          HAL_I2C_Master_Transmit(&hi2c3,0x40,commands,2,10);
//          if(commands[0]==18\
//          || commands[0]==19\
//          || commands[0]==20\
//          || commands[0]==21\
//          || commands[0]==28\
//          || commands[0]==30\
//          || commands[0]==32\
//          || commands[0]==34){
//            if(ctrlBuffer[32]-ctrlBuffer[28]+1>0){
//              frameSizeWidth=ctrlBuffer[32]-ctrlBuffer[28]+1;
//            }
//            if(ctrlBuffer[34]-ctrlBuffer[30]+1>0){
//              frameSizeHeight=ctrlBuffer[34]-ctrlBuffer[30]+1;
//            }
//          }

//          // user_cdc_buffer.data[0]=ack;
//          CDC_Transmit_HS(user_cdc_buffer.data,1);
//          break;
//      /**
//       * i2c write all
//       *   cdc => ctrlBuffer => I2C(maximum 256 bytes)
//       *   ack => cdc 36(1byte)
//       */
//        case 36:
//          // ctrlBuffer[user_cdc_buffer.data[1]]=user_cdc_buffer.data[2];
//          // user_cdc_buffer.data[0]=ack;
//          CDC_Transmit_HS(user_cdc_buffer.data,1);
//          break;
//      /**
//       * i2c read special address
//       *   I2C => ctrlBuffer[x]
//       *   ack + ctrlBuffer[x] => cdc ack+data(2 bytes)
//       */
//        case 97:
//          // user_cdc_buffer.data[0]=ack=>97;
//          HAL_I2C_Master_Transmit(&hi2c3,0x40,&user_cdc_buffer.data[1],1,10);
//          if(HAL_I2C_Master_Receive(&hi2c3,0x40,&ctrlBuffer[user_cdc_buffer.data[1]],1,10)==HAL_OK){
//						user_cdc_buffer.data[1]=ctrlBuffer[user_cdc_buffer.data[1]];
//					}
//					else{
//						user_cdc_buffer.data[1]=0;
//					}
//          CDC_Transmit_HS(user_cdc_buffer.data,2);
//          break;
//      /**
//       * i2c read all
//       *   ack => cdc 100(1 byte)
//       *   I2C => ctrlBuffer => cdc(maximum 256 bytes)
//       */
//        case 100:
//          // user_cdc_buffer.data[0]=ack=>100;
//          CDC_Transmit_HS(user_cdc_buffer.data,1);
//          for(commands[0]=0;commands[0]<sizeof(ctrlBuffer);commands[0]++){
//            HAL_I2C_Master_Transmit(&hi2c3,0x40,commands,1,10);
//            if(HAL_I2C_Master_Receive(&hi2c3,0x40,&ctrlBuffer[commands[0]],1,10)!=HAL_OK){
//							ctrlBuffer[commands[0]]=0;
//						}
//          }
//          CDC_Transmit_HS(ctrlBuffer,sizeof(ctrlBuffer));
//          break;
//        default:
//          break;
//      }
//      user_cdc_buffer.len = 0;
//    }

////    if(imgRead==1 && ready==1){
////      if(frameReady==0){
////        CDC_Transmit_HS(&imgBuffer[2],2*frameSizeWidth*frameSizeHeight);
////      }
////      else if(frameReady==1){
////        imgBuffer[4*frameSizeWidth*frameSizeHeight]=imgBuffer[0];
////        imgBuffer[4*frameSizeWidth*frameSizeHeight+1]=imgBuffer[1];
////        CDC_Transmit_HS(&imgBuffer[2+2*frameSizeWidth*frameSizeHeight],2*frameSizeWidth*frameSizeHeight);
////      }
////      imgRead=0;
////    }

//    if(imgRead==2){
//      CDC_Transmit_HS((uint8_t*)img.calibration,36);
//      imgRead=0;
//    }

		ScreenDrawLoop(&img);

    /* USER CODE END WHILE */

  }
}

void SystemClock_Config(void)
{
  RCC_OscInitTypeDef RCC_OscInitStruct = {0};
  RCC_ClkInitTypeDef RCC_ClkInitStruct = {0};
  RCC_PeriphCLKInitTypeDef PeriphClkInitStruct = {0};

  /** Configure the main internal regulator output voltage
  */
  __HAL_RCC_PWR_CLK_ENABLE();
  __HAL_PWR_VOLTAGESCALING_CONFIG(PWR_REGULATOR_VOLTAGE_SCALE1);
  /** Initializes the RCC Oscillators according to the specified parameters
  * in the RCC_OscInitTypeDef structure.
  */
  RCC_OscInitStruct.OscillatorType = RCC_OSCILLATORTYPE_HSE;
  RCC_OscInitStruct.HSEState = RCC_HSE_ON;
  RCC_OscInitStruct.PLL.PLLState = RCC_PLL_ON;
  RCC_OscInitStruct.PLL.PLLSource = RCC_PLLSOURCE_HSE;
  RCC_OscInitStruct.PLL.PLLM = 4;
  RCC_OscInitStruct.PLL.PLLN = 168;
  RCC_OscInitStruct.PLL.PLLP = RCC_PLLP_DIV2;
  RCC_OscInitStruct.PLL.PLLQ = 7;
  if (HAL_RCC_OscConfig(&RCC_OscInitStruct) != HAL_OK)
  {
    Error_Handler();
  }
  /** Initializes the CPU, AHB and APB buses clocks
  */
  RCC_ClkInitStruct.ClockType = RCC_CLOCKTYPE_HCLK|RCC_CLOCKTYPE_SYSCLK
                              |RCC_CLOCKTYPE_PCLK1|RCC_CLOCKTYPE_PCLK2;
  RCC_ClkInitStruct.SYSCLKSource = RCC_SYSCLKSOURCE_PLLCLK;
  RCC_ClkInitStruct.AHBCLKDivider = RCC_SYSCLK_DIV1;
  RCC_ClkInitStruct.APB1CLKDivider = RCC_HCLK_DIV4;
  RCC_ClkInitStruct.APB2CLKDivider = RCC_HCLK_DIV2;

  if (HAL_RCC_ClockConfig(&RCC_ClkInitStruct, FLASH_LATENCY_5) != HAL_OK)
  {
    Error_Handler();
  }
  PeriphClkInitStruct.PeriphClockSelection = RCC_PERIPHCLK_LTDC;
  PeriphClkInitStruct.PLLSAI.PLLSAIN = 50;
  PeriphClkInitStruct.PLLSAI.PLLSAIR = 2;
  PeriphClkInitStruct.PLLSAIDivR = RCC_PLLSAIDIVR_2;
  if (HAL_RCCEx_PeriphCLKConfig(&PeriphClkInitStruct) != HAL_OK)
  {
    Error_Handler();
  }
}

/* USER CODE BEGIN 4 */

void HAL_TIM_PWM_PulseFinishedCallback(TIM_HandleTypeDef *htim){
	if(htim->Instance==TIM5){
//		if(ADC_select==ADC_Internal){
//			HAL_SPI_Receive(&hspi4,(uint8_t*)img.image+img.pixel*2,1,1);
//		}else
		if(ADC_select==ADC_External){
			HAL_SPI_Receive(&hspi3,(uint8_t*)img.image+img.pixel*2,1,1);
		}
		if( img.pixel==  0 || img.pixel== 23 ||
				img.pixel== 46 || img.pixel== 69 ||
				img.pixel== 92 || img.pixel==115 ||
				img.pixel==138 || img.pixel==161 ||
				img.pixel==184 || img.pixel==207 ||
				img.pixel==230 || img.pixel==253 ||
				img.pixel==276 || img.pixel==299 ||
				img.pixel==322 || img.pixel==345 ||
				img.pixel==368 || img.pixel==391 ||
				img.pixel==414 || img.pixel==437 ||
				img.pixel==460 || img.pixel==483){
			imageValue[img.pixel/23]=img.image[0][img.pixel];
			img.image[0][img.pixel]=0;
		}
		img.pixel=(img.pixel<483)? img.pixel+1:0;
	}
}

/* USER CODE END 4 */

 /**
  * @brief  Period elapsed callback in non blocking mode
  * @note   This function is called  when TIM6 interrupt took place, inside
  * HAL_TIM_IRQHandler(). It makes a direct call to HAL_IncTick() to increment
  * a global variable "uwTick" used as application time base.
  * @param  htim : TIM handle
  * @retval None
  */
void HAL_TIM_PeriodElapsedCallback(TIM_HandleTypeDef *htim)
{
  /* USER CODE BEGIN Callback 0 */

	// Timer 4 PWM Channel 2 generates ADC_CNV signal to Ext ADC
	if(htim->Instance==TIM3){
		HAL_GPIO_TogglePin(LD4_GPIO_Port,LD4_Pin);
//		HAL_TIM_PWM_Start_IT(&htim4,TIM_CHANNEL_2);
		uint8_t reg=0;
		HAL_I2C_Init(&hi2c3);
		HAL_I2C_Master_Transmit(&hi2c3,48,&reg,1,10);
		HAL_I2C_Master_Receive(&hi2c3,48,(uint8_t*)(img.calibration),24,10);
		HAL_Delay(1);
		reg=100;
		HAL_I2C_Master_Transmit(&hi2c3,48,&reg,1,10);
		HAL_I2C_Master_Receive(&hi2c3,48,(uint8_t*)(img.image[0]),968,100);
	}

  /* USER CODE END Callback 0 */
  if (htim->Instance == TIM6) {
    HAL_IncTick();
  }
}

void Error_Handler(void)
{
}

/************************ (C) COPYRIGHT STMicroelectronics *****END OF FILE****/
